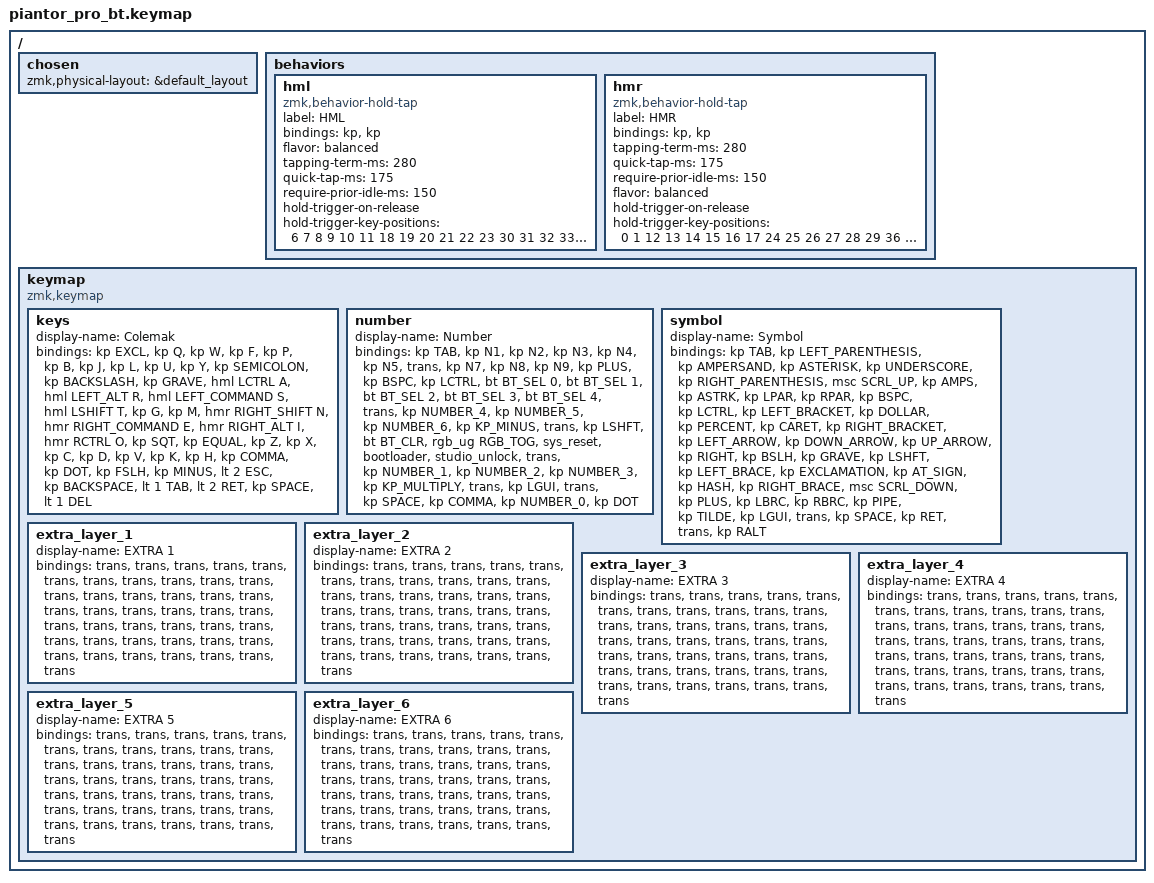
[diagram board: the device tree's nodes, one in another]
/*
 * Copyright (c) 2020 The ZMK Contributors
 *
 * SPDX-License-Identifier: MIT
 */

#include <behaviors.dtsi>
#include <dt-bindings/zmk/bt.h>
#include <dt-bindings/zmk/keys.h>
#include <dt-bindings/zmk/pointing.h>
#include <dt-bindings/zmk/rgb.h>

/ {
    chosen { zmk,physical-layout = &default_layout; };
};

/ {
    behaviors {
        hml: hml {
            compatible = "zmk,behavior-hold-tap";
            label = "HML";
            bindings = <&kp>, <&kp>;

            #binding-cells = <2>;
            flavor = "balanced";
            tapping-term-ms = <280>;
            quick-tap-ms = <175>;
            require-prior-idle-ms = <150>;
            hold-trigger-on-release;
            hold-trigger-key-positions = <6 7 8 9 10 11 18 19 20 21 22 23 30 31 32 33 34 35 40 41 36 37 38 39>;
        };

        hmr: hmr {
            compatible = "zmk,behavior-hold-tap";
            label = "HMR";
            bindings = <&kp>, <&kp>;

            #binding-cells = <2>;
            tapping-term-ms = <280>;
            quick-tap-ms = <175>;
            require-prior-idle-ms = <150>;
            flavor = "balanced";
            hold-trigger-on-release;
            hold-trigger-key-positions = <0 1 12 13 14 15 16 17 24 25 26 27 28 29 36 37 38 2 3 4 5 39 40 41>;
        };
    };

    keymap {
        compatible = "zmk,keymap";

        keys {
            display-name = "Colemak";

            // --------------------------------------------------------------------------------
            // |  TAB |  Q  |  W  |  E  |  R  |  T  |  Y  |  U   |  I  |  O  |  P  | BSPC |
            // | CTRL |  A  |  S  |  D  |  F  |  G  |  H  |  J   |  K  |  L  |  ;  |  '   |
            // | SHFT |  Z  |  X  |  C  |  V  |  B  |  N  |  M   |  ,  |  .  |  /  | ESC  |
            //                    | GUI | LWR | SPC | ENT | RSE  | ALT |

            bindings = <
&kp EXCL  &kp Q  &kp W  &kp F  &kp P  &kp B  &kp J  &kp L  &kp U  &kp Y  &kp SEMICOLON  &kp BACKSLASH  &kp GRAVE  &hml LCTRL A  &hml LEFT_ALT R  &hml LEFT_COMMAND S  &hml LSHIFT T  &kp G  &kp M  &hmr RIGHT_SHIFT N  &hmr RIGHT_COMMAND E  &hmr RIGHT_ALT I  &hmr RCTRL O  &kp SQT  &kp EQUAL  &kp Z  &kp X  &kp C  &kp D  &kp V  &kp K  &kp H  &kp COMMA  &kp DOT  &kp FSLH  &kp MINUS  &lt 2 ESC  &kp BACKSPACE  &lt 1 TAB  &lt 2 RET  &kp SPACE  &lt 1 DEL
            >;
        };

        number {
            display-name = "Number";

            // -----------------------------------------------------------------------------------------
            // |  TAB |  1  |  2  |  3  |  4  |  5    |  6  |  7  |  8  |  9  |  0  | BSPC |
            // | CTRL | BT1 | BT2 | BT3 | BT4 | BT5   | LFT | DWN |  UP | RGT |     |      |
            // | SHFT | BTCR| RGB | RST | BOOT| Unlock|     |     |     |     |     |      |
            //                    | GUI |     | SPC   | ENT |     | ALT |

            bindings = <
&kp TAB  &kp N1  &kp N2  &kp N3  &kp N4  &kp N5  &trans  &kp N7  &kp N8  &kp N9  &kp PLUS  &kp BSPC  &kp LCTRL  &bt BT_SEL 0  &bt BT_SEL 1  &bt BT_SEL 2  &bt BT_SEL 3  &bt BT_SEL 4  &trans  &kp NUMBER_4  &kp NUMBER_5  &kp NUMBER_6  &kp KP_MINUS  &trans  &kp LSHFT  &bt BT_CLR  &rgb_ug RGB_TOG  &sys_reset  &bootloader  &studio_unlock  &trans  &kp NUMBER_1  &kp NUMBER_2  &kp NUMBER_3  &kp KP_MULTIPLY  &trans  &kp LGUI  &trans  &kp SPACE  &kp COMMA  &kp NUMBER_0  &kp DOT
            >;
        };

        symbol {
            display-name = "Symbol";

            // -----------------------------------------------------------------------------------------
            // |  TAB |  !  |  @  |  #  |  $  |  %  |  ^  |  &  |  *  |  (  |  )  | BSPC |
            // | CTRL | HUD | HUI |     |     |     |  -  |  =  |  [  |  ]  |  \  |  `   |
            // | SHFT |     |     |     |     |     |  _  |  +  |  {  |  }  | "|" |  ~   |
            //                    | GUI |     | SPC | ENT |     | ALT |

            bindings = <
&kp TAB  &kp LEFT_PARENTHESIS  &kp AMPERSAND  &kp ASTERISK  &kp UNDERSCORE  &kp RIGHT_PARENTHESIS  &msc SCRL_UP  &kp AMPS  &kp ASTRK  &kp LPAR  &kp RPAR  &kp BSPC  &kp LCTRL  &kp LEFT_BRACKET  &kp DOLLAR  &kp PERCENT  &kp CARET  &kp RIGHT_BRACKET  &kp LEFT_ARROW  &kp DOWN_ARROW  &kp UP_ARROW  &kp RIGHT  &kp BSLH  &kp GRAVE  &kp LSHFT  &kp LEFT_BRACE  &kp EXCLAMATION  &kp AT_SIGN  &kp HASH  &kp RIGHT_BRACE  &msc SCRL_DOWN  &kp PLUS  &kp LBRC  &kp RBRC  &kp PIPE  &kp TILDE  &kp LGUI  &trans  &kp SPACE  &kp RET  &trans  &kp RALT
            >;
        };

        extra_layer_1 {
            display-name = "EXTRA 1";
            bindings = <
&trans  &trans  &trans  &trans  &trans  &trans  &trans  &trans  &trans  &trans  &trans  &trans  &trans  &trans  &trans  &trans  &trans  &trans  &trans  &trans  &trans  &trans  &trans  &trans  &trans  &trans  &trans  &trans  &trans  &trans  &trans  &trans  &trans  &trans  &trans  &trans  &trans  &trans  &trans  &trans  &trans  &trans
            >;
        };

        extra_layer_2 {
            display-name = "EXTRA 2";
            bindings = <
&trans  &trans  &trans  &trans  &trans  &trans  &trans  &trans  &trans  &trans  &trans  &trans  &trans  &trans  &trans  &trans  &trans  &trans  &trans  &trans  &trans  &trans  &trans  &trans  &trans  &trans  &trans  &trans  &trans  &trans  &trans  &trans  &trans  &trans  &trans  &trans  &trans  &trans  &trans  &trans  &trans  &trans
            >;
        };

        extra_layer_3 {
            display-name = "EXTRA 3";
            bindings = <
&trans  &trans  &trans  &trans  &trans  &trans  &trans  &trans  &trans  &trans  &trans  &trans  &trans  &trans  &trans  &trans  &trans  &trans  &trans  &trans  &trans  &trans  &trans  &trans  &trans  &trans  &trans  &trans  &trans  &trans  &trans  &trans  &trans  &trans  &trans  &trans  &trans  &trans  &trans  &trans  &trans  &trans
            >;
        };

        extra_layer_4 {
            display-name = "EXTRA 4";
            bindings = <
&trans  &trans  &trans  &trans  &trans  &trans  &trans  &trans  &trans  &trans  &trans  &trans  &trans  &trans  &trans  &trans  &trans  &trans  &trans  &trans  &trans  &trans  &trans  &trans  &trans  &trans  &trans  &trans  &trans  &trans  &trans  &trans  &trans  &trans  &trans  &trans  &trans  &trans  &trans  &trans  &trans  &trans
            >;
        };

        extra_layer_5 {
            display-name = "EXTRA 5";
            bindings = <
&trans  &trans  &trans  &trans  &trans  &trans  &trans  &trans  &trans  &trans  &trans  &trans  &trans  &trans  &trans  &trans  &trans  &trans  &trans  &trans  &trans  &trans  &trans  &trans  &trans  &trans  &trans  &trans  &trans  &trans  &trans  &trans  &trans  &trans  &trans  &trans  &trans  &trans  &trans  &trans  &trans  &trans
            >;
        };

        extra_layer_6 {
            display-name = "EXTRA 6";
            bindings = <
&trans  &trans  &trans  &trans  &trans  &trans  &trans  &trans  &trans  &trans  &trans  &trans  &trans  &trans  &trans  &trans  &trans  &trans  &trans  &trans  &trans  &trans  &trans  &trans  &trans  &trans  &trans  &trans  &trans  &trans  &trans  &trans  &trans  &trans  &trans  &trans  &trans  &trans  &trans  &trans  &trans  &trans
            >;
        };
    };
};
